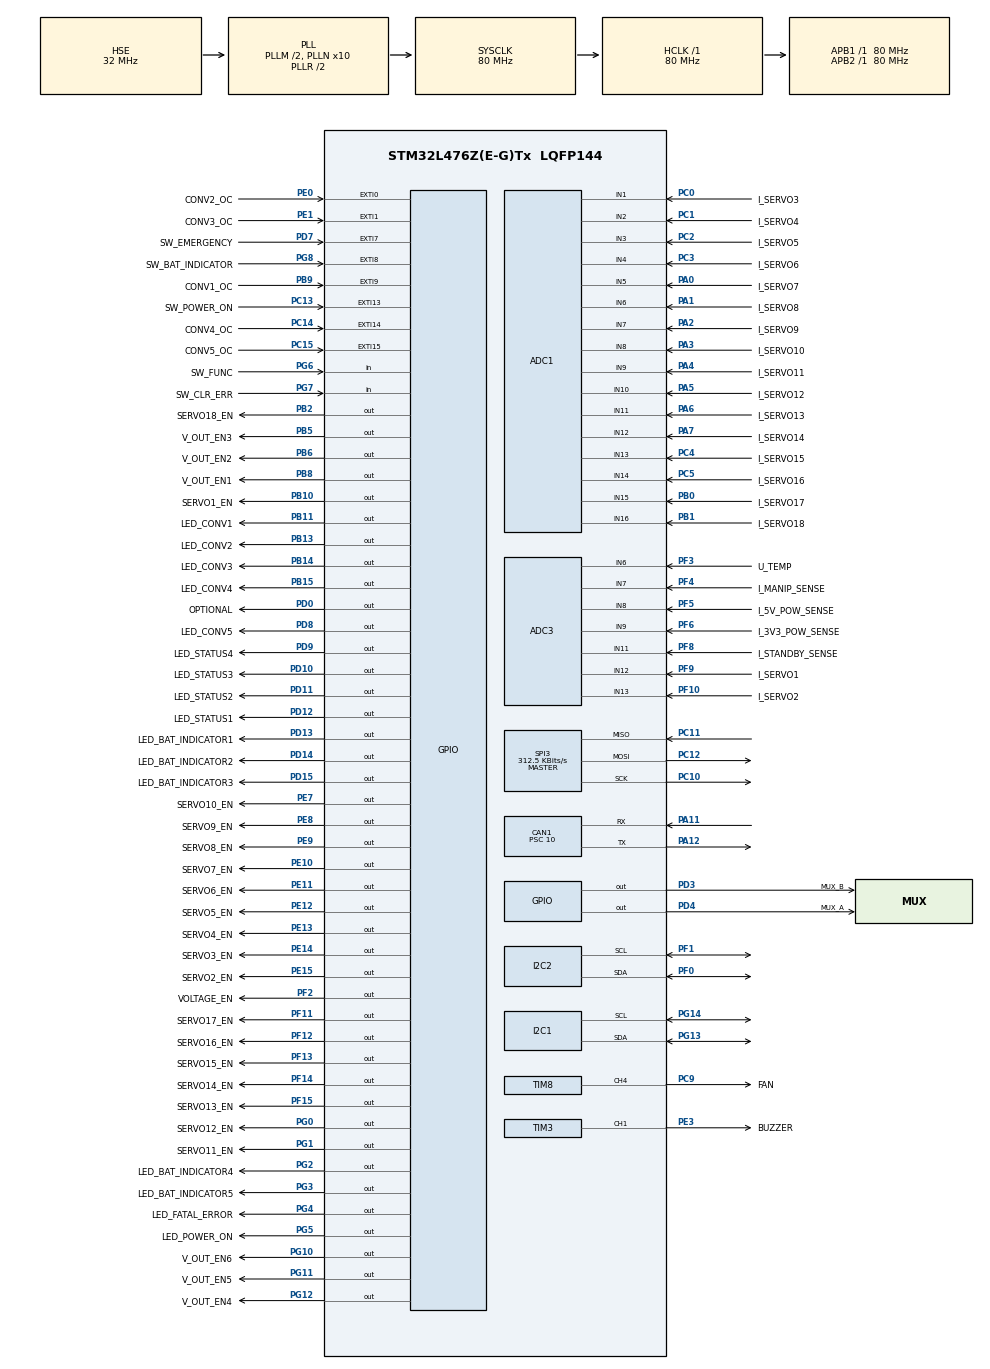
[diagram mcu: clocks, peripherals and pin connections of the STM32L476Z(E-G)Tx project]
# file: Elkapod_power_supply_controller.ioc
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ADC1.Channel-0\#ChannelRegularConversion=ADC_CHANNEL_1
ADC1.Channel-1\#ChannelRegularConversion=ADC_CHANNEL_2
ADC1.Channel-10\#ChannelRegularConversion=ADC_CHANNEL_11
ADC1.Channel-11\#ChannelRegularConversion=ADC_CHANNEL_12
ADC1.Channel-12\#ChannelRegularConversion=ADC_CHANNEL_13
ADC1.Channel-13\#ChannelRegularConversion=ADC_CHANNEL_14
ADC1.Channel-14\#ChannelRegularConversion=ADC_CHANNEL_15
ADC1.Channel-15\#ChannelRegularConversion=ADC_CHANNEL_16
ADC1.Channel-2\#ChannelRegularConversion=ADC_CHANNEL_3
ADC1.Channel-3\#ChannelRegularConversion=ADC_CHANNEL_4
ADC1.Channel-4\#ChannelRegularConversion=ADC_CHANNEL_5
ADC1.Channel-5\#ChannelRegularConversion=ADC_CHANNEL_6
ADC1.Channel-6\#ChannelRegularConversion=ADC_CHANNEL_7
ADC1.Channel-7\#ChannelRegularConversion=ADC_CHANNEL_8
ADC1.Channel-8\#ChannelRegularConversion=ADC_CHANNEL_9
ADC1.Channel-9\#ChannelRegularConversion=ADC_CHANNEL_10
ADC1.ClockPrescaler=ADC_CLOCK_ASYNC_DIV4
ADC1.ContinuousConvMode=DISABLE
ADC1.DMAContinuousRequests=DISABLE
ADC1.EOCSelection=ADC_EOC_SEQ_CONV
ADC1.ExternalTrigConv=ADC_SOFTWARE_START
ADC1.NbrOfConversion=16
ADC1.NbrOfConversionFlag=1
ADC1.OffsetNumber-0\#ChannelRegularConversion=ADC_OFFSET_NONE
ADC1.OffsetNumber-1\#ChannelRegularConversion=ADC_OFFSET_NONE
ADC1.OffsetNumber-10\#ChannelRegularConversion=ADC_OFFSET_NONE
ADC1.OffsetNumber-11\#ChannelRegularConversion=ADC_OFFSET_NONE
ADC1.OffsetNumber-12\#ChannelRegularConversion=ADC_OFFSET_NONE
ADC1.OffsetNumber-13\#ChannelRegularConversion=ADC_OFFSET_NONE
ADC1.OffsetNumber-14\#ChannelRegularConversion=ADC_OFFSET_NONE
ADC1.OffsetNumber-15\#ChannelRegularConversion=ADC_OFFSET_NONE
ADC1.OffsetNumber-2\#ChannelRegularConversion=ADC_OFFSET_NONE
ADC1.OffsetNumber-3\#ChannelRegularConversion=ADC_OFFSET_NONE
ADC1.OffsetNumber-4\#ChannelRegularConversion=ADC_OFFSET_NONE
ADC1.OffsetNumber-5\#ChannelRegularConversion=ADC_OFFSET_NONE
ADC1.OffsetNumber-6\#ChannelRegularConversion=ADC_OFFSET_NONE
ADC1.OffsetNumber-7\#ChannelRegularConversion=ADC_OFFSET_NONE
ADC1.OffsetNumber-8\#ChannelRegularConversion=ADC_OFFSET_NONE
ADC1.OffsetNumber-9\#ChannelRegularConversion=ADC_OFFSET_NONE
ADC1.Overrun=ADC_OVR_DATA_PRESERVED
ADC1.OversamplingMode=DISABLE
ADC1.Rank-0\#ChannelRegularConversion=1
ADC1.Rank-1\#ChannelRegularConversion=2
ADC1.Rank-10\#ChannelRegularConversion=11
ADC1.Rank-11\#ChannelRegularConversion=12
ADC1.Rank-12\#ChannelRegularConversion=13
ADC1.Rank-13\#ChannelRegularConversion=14
ADC1.Rank-14\#ChannelRegularConversion=15
ADC1.Rank-15\#ChannelRegularConversion=16
ADC1.Rank-2\#ChannelRegularConversion=3
ADC1.Rank-3\#ChannelRegularConversion=4
ADC1.Rank-4\#ChannelRegularConversion=5
ADC1.Rank-5\#ChannelRegularConversion=6
ADC1.Rank-6\#ChannelRegularConversion=7
ADC1.Rank-7\#ChannelRegularConversion=8
ADC1.Rank-8\#ChannelRegularConversion=9
ADC1.Rank-9\#ChannelRegularConversion=10
ADC1.SamplingTime-0\#ChannelRegularConversion=ADC_SAMPLETIME_12CYCLES_5
ADC1.SamplingTime-1\#ChannelRegularConversion=ADC_SAMPLETIME_12CYCLES_5
ADC1.SamplingTime-10\#ChannelRegularConversion=ADC_SAMPLETIME_12CYCLES_5
ADC1.SamplingTime-11\#ChannelRegularConversion=ADC_SAMPLETIME_12CYCLES_5
ADC1.SamplingTime-12\#ChannelRegularConversion=ADC_SAMPLETIME_12CYCLES_5
ADC1.SamplingTime-13\#ChannelRegularConversion=ADC_SAMPLETIME_12CYCLES_5
ADC1.SamplingTime-14\#ChannelRegularConversion=ADC_SAMPLETIME_12CYCLES_5
ADC1.SamplingTime-15\#ChannelRegularConversion=ADC_SAMPLETIME_12CYCLES_5
ADC1.SamplingTime-2\#ChannelRegularConversion=ADC_SAMPLETIME_12CYCLES_5
ADC1.SamplingTime-3\#ChannelRegularConversion=ADC_SAMPLETIME_12CYCLES_5
ADC1.SamplingTime-4\#ChannelRegularConversion=ADC_SAMPLETIME_12CYCLES_5
ADC1.SamplingTime-5\#ChannelRegularConversion=ADC_SAMPLETIME_12CYCLES_5
ADC1.SamplingTime-6\#ChannelRegularConversion=ADC_SAMPLETIME_12CYCLES_5
ADC1.SamplingTime-7\#ChannelRegularConversion=ADC_SAMPLETIME_12CYCLES_5
ADC1.SamplingTime-8\#ChannelRegularConversion=ADC_SAMPLETIME_12CYCLES_5
ADC1.SamplingTime-9\#ChannelRegularConversion=ADC_SAMPLETIME_12CYCLES_5
ADC1.master=1
ADC3.Channel-1\#ChannelRegularConversion=ADC_CHANNEL_6
ADC3.Channel-2\#ChannelRegularConversion=ADC_CHANNEL_7
ADC3.Channel-3\#ChannelRegularConversion=ADC_CHANNEL_8
ADC3.Channel-4\#ChannelRegularConversion=ADC_CHANNEL_9
ADC3.Channel-5\#ChannelRegularConversion=ADC_CHANNEL_11
ADC3.Channel-6\#ChannelRegularConversion=ADC_CHANNEL_12
ADC3.Channel-7\#ChannelRegularConversion=ADC_CHANNEL_13
ADC3.ClockPrescaler=ADC_CLOCK_ASYNC_DIV4
ADC3.EOCSelection=ADC_EOC_SEQ_CONV
ADC3.NbrOfConversion=7
ADC3.NbrOfConversionFlag=1
ADC3.OffsetNumber-1\#ChannelRegularConversion=ADC_OFFSET_NONE
ADC3.OffsetNumber-2\#ChannelRegularConversion=ADC_OFFSET_NONE
ADC3.OffsetNumber-3\#ChannelRegularConversion=ADC_OFFSET_NONE
ADC3.OffsetNumber-4\#ChannelRegularConversion=ADC_OFFSET_NONE
ADC3.OffsetNumber-5\#ChannelRegularConversion=ADC_OFFSET_NONE
ADC3.OffsetNumber-6\#ChannelRegularConversion=ADC_OFFSET_NONE
ADC3.OffsetNumber-7\#ChannelRegularConversion=ADC_OFFSET_NONE
ADC3.Rank-1\#ChannelRegularConversion=1
ADC3.Rank-2\#ChannelRegularConversion=2
ADC3.Rank-3\#ChannelRegularConversion=3
ADC3.Rank-4\#ChannelRegularConversion=4
ADC3.Rank-5\#ChannelRegularConversion=5
ADC3.Rank-6\#ChannelRegularConversion=6
ADC3.Rank-7\#ChannelRegularConversion=7
ADC3.SamplingTime-1\#ChannelRegularConversion=ADC_SAMPLETIME_12CYCLES_5
ADC3.SamplingTime-2\#ChannelRegularConversion=ADC_SAMPLETIME_12CYCLES_5
ADC3.SamplingTime-3\#ChannelRegularConversion=ADC_SAMPLETIME_12CYCLES_5
ADC3.SamplingTime-4\#ChannelRegularConversion=ADC_SAMPLETIME_12CYCLES_5
ADC3.SamplingTime-5\#ChannelRegularConversion=ADC_SAMPLETIME_12CYCLES_5
ADC3.SamplingTime-6\#ChannelRegularConversion=ADC_SAMPLETIME_12CYCLES_5
ADC3.SamplingTime-7\#ChannelRegularConversion=ADC_SAMPLETIME_12CYCLES_5
CAN1.AWUM=ENABLE
CAN1.BS1=CAN_BS1_6TQ
CAN1.CalculateBaudRate=1000000
CAN1.CalculateTimeBit=1000
CAN1.CalculateTimeQuantum=125.0
CAN1.NART=ENABLE
CAN1.Prescaler=10
Dma.ADC1.0.Direction=DMA_PERIPH_TO_MEMORY
Dma.ADC1.0.Instance=DMA1_Channel1
Dma.ADC1.0.MemDataAlignment=DMA_MDATAALIGN_HALFWORD
Dma.ADC1.0.MemInc=DMA_MINC_ENABLE
Dma.ADC1.0.Mode=DMA_NORMAL
Dma.ADC1.0.PeriphDataAlignment=DMA_PDATAALIGN_HALFWORD
Dma.ADC1.0.PeriphInc=DMA_PINC_DISABLE
Dma.ADC1.0.Priority=DMA_PRIORITY_MEDIUM
Dma.ADC3.5.Direction=DMA_PERIPH_TO_MEMORY
Dma.ADC3.5.Instance=DMA1_Channel3
Dma.ADC3.5.MemDataAlignment=DMA_MDATAALIGN_HALFWORD
Dma.ADC3.5.MemInc=DMA_MINC_ENABLE
Dma.ADC3.5.Mode=DMA_NORMAL
Dma.ADC3.5.PeriphDataAlignment=DMA_PDATAALIGN_HALFWORD
Dma.ADC3.5.PeriphInc=DMA_PINC_DISABLE
Dma.ADC3.5.Priority=DMA_PRIORITY_MEDIUM
Dma.I2C2_RX.1.Direction=DMA_PERIPH_TO_MEMORY
Dma.I2C2_RX.1.Instance=DMA1_Channel5
Dma.I2C2_RX.1.MemDataAlignment=DMA_MDATAALIGN_BYTE
Dma.I2C2_RX.1.MemInc=DMA_MINC_ENABLE
Dma.I2C2_RX.1.Mode=DMA_NORMAL
Dma.I2C2_RX.1.PeriphDataAlignment=DMA_PDATAALIGN_BYTE
Dma.I2C2_RX.1.PeriphInc=DMA_PINC_DISABLE
Dma.I2C2_RX.1.Priority=DMA_PRIORITY_HIGH
Dma.I2C2_TX.2.Direction=DMA_MEMORY_TO_PERIPH
Dma.I2C2_TX.2.Instance=DMA1_Channel4
Dma.I2C2_TX.2.MemDataAlignment=DMA_MDATAALIGN_BYTE
Dma.I2C2_TX.2.MemInc=DMA_MINC_DISABLE
Dma.I2C2_TX.2.Mode=DMA_NORMAL
Dma.I2C2_TX.2.PeriphDataAlignment=DMA_PDATAALIGN_BYTE
Dma.I2C2_TX.2.PeriphInc=DMA_PINC_DISABLE
Dma.I2C2_TX.2.Priority=DMA_PRIORITY_HIGH
Dma.Request0=ADC1
Dma.Request1=I2C2_RX
Dma.Request2=I2C2_TX
Dma.Request3=SPI3_RX
Dma.Request4=SPI3_TX
Dma.Request5=ADC3
Dma.SPI3_RX.3.Direction=DMA_PERIPH_TO_MEMORY
Dma.SPI3_RX.3.Instance=DMA2_Channel1
Dma.SPI3_RX.3.MemDataAlignment=DMA_MDATAALIGN_BYTE
Dma.SPI3_RX.3.MemInc=DMA_MINC_ENABLE
Dma.SPI3_RX.3.Mode=DMA_NORMAL
Dma.SPI3_RX.3.PeriphDataAlignment=DMA_PDATAALIGN_BYTE
Dma.SPI3_RX.3.PeriphInc=DMA_PINC_DISABLE
Dma.SPI3_RX.3.Priority=DMA_PRIORITY_HIGH
Dma.SPI3_TX.4.Direction=DMA_MEMORY_TO_PERIPH
Dma.SPI3_TX.4.Instance=DMA2_Channel2
Dma.SPI3_TX.4.MemDataAlignment=DMA_MDATAALIGN_BYTE
Dma.SPI3_TX.4.MemInc=DMA_MINC_ENABLE
Dma.SPI3_TX.4.Mode=DMA_NORMAL
Dma.SPI3_TX.4.PeriphDataAlignment=DMA_PDATAALIGN_BYTE
Dma.SPI3_TX.4.PeriphInc=DMA_PINC_DISABLE
Dma.SPI3_TX.4.Priority=DMA_PRIORITY_HIGH
I2C1.Timing=0x10D19CE4
I2C2.Analog_Filter=I2C_ANALOGFILTER_DISABLE
I2C2.Timing=0x10D19EE6
Mcu.Family=STM32L4
Mcu.Name=STM32L476Z(E-G)Tx
Mcu.Package=LQFP144
NVIC.CAN1_RX0_IRQn=true\:0\:0\:false\:false\:true\:true\:true\:true
NVIC.DMA1_Channel1_IRQn=true\:0\:0\:false\:false\:true\:false\:true\:true
NVIC.DMA1_Channel3_IRQn=true\:0\:0\:false\:false\:true\:false\:true\:true
NVIC.DMA1_Channel4_IRQn=true\:0\:0\:false\:false\:true\:false\:true\:true
NVIC.DMA1_Channel5_IRQn=true\:0\:0\:false\:false\:true\:false\:true\:true
NVIC.DMA2_Channel1_IRQn=true\:0\:0\:false\:false\:true\:false\:true\:true
NVIC.DMA2_Channel2_IRQn=true\:0\:0\:false\:false\:true\:false\:true\:true
NVIC.EXTI0_IRQn=true\:0\:0\:false\:false\:true\:true\:true\:true
NVIC.EXTI15_10_IRQn=true\:0\:0\:false\:false\:true\:true\:true\:true
NVIC.EXTI1_IRQn=true\:0\:0\:false\:false\:true\:true\:true\:true
NVIC.EXTI9_5_IRQn=true\:0\:0\:false\:false\:true\:true\:true\:true
NVIC.I2C2_ER_IRQn=true\:0\:0\:false\:false\:true\:true\:true\:true
NVIC.I2C2_EV_IRQn=true\:0\:0\:false\:false\:true\:true\:true\:true
NVIC.PriorityGroup=NVIC_PRIORITYGROUP_4
NVIC.TIM1_TRG_COM_TIM17_IRQn=true\:0\:0\:false\:false\:true\:true\:true\:true
NVIC.TIM7_IRQn=true\:0\:0\:false\:false\:true\:true\:true\:true
PA0.GPIO_Label=I_SERVO7
PA0.Signal=ADCx_IN5
PA1.GPIO_Label=I_SERVO8
PA1.Signal=ADCx_IN6
PA11.Mode=CAN_Activate
PA11.Signal=CAN1_RX
PA12.Mode=CAN_Activate
PA12.Signal=CAN1_TX
PA13\ (JTMS-SWDIO).Mode=Serial_Wire
PA13\ (JTMS-SWDIO).Signal=SYS_JTMS-SWDIO
PA14\ (JTCK-SWCLK).Mode=Serial_Wire
PA14\ (JTCK-SWCLK).Signal=SYS_JTCK-SWCLK
PA2.GPIO_Label=I_SERVO9
PA2.Signal=ADCx_IN7
PA3.GPIO_Label=I_SERVO10
PA3.Signal=ADCx_IN8
PA4.GPIO_Label=I_SERVO11
PA4.Signal=ADCx_IN9
PA5.GPIO_Label=I_SERVO12
PA5.Signal=ADCx_IN10
PA6.GPIO_Label=I_SERVO13
PA6.Signal=ADCx_IN11
PA7.GPIO_Label=I_SERVO14
PA7.Signal=ADCx_IN12
PB0.GPIO_Label=I_SERVO17
PB0.Signal=ADCx_IN15
PB1.GPIO_Label=I_SERVO18
PB1.Signal=ADCx_IN16
PB10.GPIO_Label=SERVO1_EN
PB10.Signal=GPIO_Output
PB11.GPIO_Label=LED_CONV1
PB11.Signal=GPIO_Output
PB13.GPIO_Label=LED_CONV2
PB13.Signal=GPIO_Output
PB14.GPIO_Label=LED_CONV3
PB14.Signal=GPIO_Output
PB15.GPIO_Label=LED_CONV4
PB15.Signal=GPIO_Output
PB2.GPIO_Label=SERVO18_EN
PB2.Signal=GPIO_Output
PB3\ (JTDO-TRACESWO).Signal=SYS_JTDO-SWO
PB5.GPIO_Label=V_OUT_EN3
PB5.Signal=GPIO_Output
PB6.GPIO_Label=V_OUT_EN2
PB6.Signal=GPIO_Output
PB8.GPIO_Label=V_OUT_EN1
PB8.Signal=GPIO_Output
PB9.GPIO_Label=CONV1_OC
PB9.Signal=GPXTI9
PC0.GPIO_Label=I_SERVO3
PC0.Signal=ADCx_IN1
PC1.GPIO_Label=I_SERVO4
PC1.Signal=ADCx_IN2
PC10.Mode=Full_Duplex_Master
PC10.Signal=SPI3_SCK
PC11.Mode=Full_Duplex_Master
PC11.Signal=SPI3_MISO
PC12.Mode=Full_Duplex_Master
PC12.Signal=SPI3_MOSI
PC13.GPIO_Label=SW_POWER_ON
PC13.GPIO_ModeDefaultEXTI=GPIO_MODE_IT_FALLING
PC13.Signal=GPXTI13
PC14-OSC32_IN\ (PC14).GPIO_Label=CONV4_OC
PC14-OSC32_IN\ (PC14).Signal=GPXTI14
PC15-OSC32_OUT\ (PC15).GPIO_Label=CONV5_OC
PC15-OSC32_OUT\ (PC15).Signal=GPXTI15
PC2.GPIO_Label=I_SERVO5
PC2.Signal=ADCx_IN3
PC3.GPIO_Label=I_SERVO6
PC3.Signal=ADCx_IN4
PC4.GPIO_Label=I_SERVO15
PC4.Signal=ADCx_IN13
PC5.GPIO_Label=I_SERVO16
PC5.Signal=ADCx_IN14
PC9.GPIO_Label=FAN
PC9.GPIO_Speed=GPIO_SPEED_FREQ_MEDIUM
PC9.Signal=S_TIM8_CH4
PD0.GPIO_Label=OPTIONAL
PD0.Signal=GPIO_Output
PD10.GPIO_Label=LED_STATUS3
PD10.Signal=GPIO_Output
PD11.GPIO_Label=LED_STATUS2
PD11.Signal=GPIO_Output
PD12.GPIO_Label=LED_STATUS1
PD12.Signal=GPIO_Output
PD13.GPIO_Label=LED_BAT_INDICATOR1
PD13.Signal=GPIO_Output
PD14.GPIO_Label=LED_BAT_INDICATOR2
PD14.Signal=GPIO_Output
PD15.GPIO_Label=LED_BAT_INDICATOR3
PD15.Signal=GPIO_Output
PD3.GPIO_Label=MUX_B
PD3.Signal=GPIO_Output
PD4.GPIO_Label=MUX_A
PD4.Signal=GPIO_Output
PD7.GPIO_Label=SW_EMERGENCY
PD7.GPIO_ModeDefaultEXTI=GPIO_MODE_IT_FALLING
PD7.Signal=GPXTI7
PD8.GPIO_Label=LED_CONV5
PD8.Signal=GPIO_Output
PD9.GPIO_Label=LED_STATUS4
PD9.Signal=GPIO_Output
PE0.GPIO_Label=CONV2_OC
PE0.Signal=GPXTI0
PE1.GPIO_Label=CONV3_OC
PE1.Signal=GPXTI1
PE10.GPIO_Label=SERVO7_EN
PE10.Signal=GPIO_Output
PE11.GPIO_Label=SERVO6_EN
PE11.Signal=GPIO_Output
PE12.GPIO_Label=SERVO5_EN
PE12.Signal=GPIO_Output
PE13.GPIO_Label=SERVO4_EN
PE13.Signal=GPIO_Output
PE14.GPIO_Label=SERVO3_EN
PE14.Signal=GPIO_Output
PE15.GPIO_Label=SERVO2_EN
PE15.Signal=GPIO_Output
PE3.GPIO_Label=BUZZER
PE3.GPIO_Speed=GPIO_SPEED_FREQ_MEDIUM
PE3.Signal=S_TIM3_CH1
PE7.GPIO_Label=SERVO10_EN
PE7.Signal=GPIO_Output
PE8.GPIO_Label=SERVO9_EN
PE8.Signal=GPIO_Output
PE9.GPIO_Label=SERVO8_EN
PE9.Signal=GPIO_Output
PF0.Mode=I2C
PF0.Signal=I2C2_SDA
PF1.Mode=I2C
PF1.Signal=I2C2_SCL
PF10.GPIO_Label=I_SERVO2
PF10.Mode=IN13-Single-Ended
PF10.Signal=ADC3_IN13
PF11.GPIO_Label=SERVO17_EN
PF11.Signal=GPIO_Output
PF12.GPIO_Label=SERVO16_EN
PF12.Signal=GPIO_Output
PF13.GPIO_Label=SERVO15_EN
PF13.Signal=GPIO_Output
PF14.GPIO_Label=SERVO14_EN
PF14.Signal=GPIO_Output
PF15.GPIO_Label=SERVO13_EN
PF15.Signal=GPIO_Output
PF2.GPIO_Label=VOLTAGE_EN
PF2.Signal=GPIO_Output
PF3.GPIO_Label=U_TEMP
PF3.Mode=IN6-Single-Ended
PF3.Signal=ADC3_IN6
PF4.GPIO_Label=I_MANIP_SENSE
PF4.Mode=IN7-Single-Ended
PF4.Signal=ADC3_IN7
PF5.GPIO_Label=I_5V_POW_SENSE
PF5.Mode=IN8-Single-Ended
PF5.Signal=ADC3_IN8
PF6.GPIO_Label=I_3V3_POW_SENSE
PF6.Mode=IN9-Single-Ended
PF6.Signal=ADC3_IN9
PF8.GPIO_Label=I_STANDBY_SENSE
PF8.Mode=IN11-Single-Ended
PF8.Signal=ADC3_IN11
PF9.GPIO_Label=I_SERVO1
PF9.Mode=IN12-Single-Ended
PF9.Signal=ADC3_IN12
PG0.GPIO_Label=SERVO12_EN
PG0.Signal=GPIO_Output
PG1.GPIO_Label=SERVO11_EN
PG1.Signal=GPIO_Output
PG10.GPIO_Label=V_OUT_EN6
PG10.Signal=GPIO_Output
PG11.GPIO_Label=V_OUT_EN5
PG11.Signal=GPIO_Output
PG12.GPIO_Label=V_OUT_EN4
PG12.Signal=GPIO_Output
PG13.Mode=I2C
PG13.Signal=I2C1_SDA
PG14.Mode=I2C
PG14.Signal=I2C1_SCL
PG2.GPIO_Label=LED_BAT_INDICATOR4
PG2.Signal=GPIO_Output
PG3.GPIO_Label=LED_BAT_INDICATOR5
PG3.Signal=GPIO_Output
PG4.GPIO_Label=LED_FATAL_ERROR
PG4.Signal=GPIO_Output
PG5.GPIO_Label=LED_POWER_ON
PG5.Signal=GPIO_Output
PG6.GPIO_Label=SW_FUNC
PG6.Signal=GPIO_Input
PG7.GPIO_Label=SW_CLR_ERR
PG7.Signal=GPIO_Input
PG8.GPIO_Label=SW_BAT_INDICATOR
PG8.GPIO_ModeDefaultEXTI=GPIO_MODE_IT_FALLING
PG8.Signal=GPXTI8
PH0-OSC_IN\ (PH0).Mode=HSE-External-Oscillator
PH0-OSC_IN\ (PH0).Signal=RCC_OSC_IN
PH1-OSC_OUT\ (PH1).Mode=HSE-External-Oscillator
PH1-OSC_OUT\ (PH1).Signal=RCC_OSC_OUT
ProjectManager.HeapSize=0x200
ProjectManager.StackSize=0x400
ProjectManager.TargetToolchain=STM32CubeIDE
RCC.ADCFreq_Value=64000000
RCC.AHBFreq_Value=80000000
RCC.APB1Freq_Value=80000000
RCC.APB1TimFreq_Value=80000000
RCC.APB2Freq_Value=80000000
RCC.APB2TimFreq_Value=80000000
RCC.CortexFreq_Value=80000000
RCC.HCLKFreq_Value=80000000
RCC.HSE_VALUE=32000000
RCC.HSI_VALUE=16000000
RCC.LSE_VALUE=32768
RCC.MSI_VALUE=4000000
RCC.PLLM=2
RCC.PLLN=10
RCC.PLLSourceVirtual=RCC_PLLSOURCE_HSE
RCC.SYSCLKFreq_VALUE=80000000
RCC.SYSCLKSource=RCC_SYSCLKSOURCE_PLLCLK
RCC.USBFreq_Value=64000000
RCC.VCOOutputFreq_Value=160000000
SH.ADCx_IN1.0=ADC1_IN1,IN1-Single-Ended
SH.ADCx_IN10.0=ADC1_IN10,IN10-Single-Ended
SH.ADCx_IN11.0=ADC1_IN11,IN11-Single-Ended
SH.ADCx_IN12.0=ADC1_IN12,IN12-Single-Ended
SH.ADCx_IN13.0=ADC1_IN13,IN13-Single-Ended
SH.ADCx_IN14.0=ADC1_IN14,IN14-Single-Ended
SH.ADCx_IN15.0=ADC1_IN15,IN15-Single-Ended
SH.ADCx_IN16.0=ADC1_IN16,IN16-Single-Ended
SH.ADCx_IN2.0=ADC1_IN2,IN2-Single-Ended
SH.ADCx_IN3.0=ADC1_IN3,IN3-Single-Ended
SH.ADCx_IN4.0=ADC1_IN4,IN4-Single-Ended
SH.ADCx_IN5.0=ADC1_IN5,IN5-Single-Ended
SH.ADCx_IN6.0=ADC1_IN6,IN6-Single-Ended
SH.ADCx_IN7.0=ADC1_IN7,IN7-Single-Ended
SH.ADCx_IN8.0=ADC1_IN8,IN8-Single-Ended
SH.ADCx_IN9.0=ADC1_IN9,IN9-Single-Ended
SH.S_TIM3_CH1.0=TIM3_CH1,PWM Generation1 CH1
SH.S_TIM8_CH4.0=TIM8_CH4,PWM Generation4 CH4
SPI3.BaudRatePrescaler=SPI_BAUDRATEPRESCALER_256
SPI3.CalculateBaudRate=312.5 KBits/s
SPI3.DataSize=SPI_DATASIZE_8BIT
SPI3.Direction=SPI_DIRECTION_2LINES
SPI3.Mode=SPI_MODE_MASTER
SPI3.VirtualType=VM_MASTER
TIM17.Period=19
TIM17.Prescaler=9999
TIM3.Channel-PWM\ Generation1\ CH1=TIM_CHANNEL_1
TIM3.Period=999
TIM3.Prescaler=79
TIM7.Period=99
TIM7.Prescaler=7999
TIM7.TIM_MasterOutputTrigger=TIM_TRGO_UPDATE
TIM8.Channel-PWM\ Generation4\ CH4=TIM_CHANNEL_4
TIM8.Period=999
TIM8.Prescaler=159
VP_SYS_V_PVD_IN.Mode=Mode_PVD_Int
VP_TIM17_VS_ClockSourceINT.Mode=Enable_Timer
VP_TIM7_VS_ClockSourceINT.Mode=Enable_Timer
board=custom

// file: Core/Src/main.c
/* USER CODE BEGIN Header */
/**
 ******************************************************************************
 * @file           : main.c
 * @brief          : Main program body
 ******************************************************************************
 * @attention
 *
 * Copyright (c) 2025 STMicroelectronics.
 * All rights reserved.
 *
 * This software is licensed under terms that can be found in the LICENSE file
 * in the root directory of this software component.
 * If no LICENSE file comes with this software, it is provided AS-IS.
 *
 ******************************************************************************
 */
/* USER CODE END Header */
#include "main.h"
#include "adc.h"
#include "can.h"
#include "dma.h"
#include "i2c.h"
#include "spi.h"
#include "tim.h"
#include "gpio.h"

/* USER CODE BEGIN Includes */
#include "hardware_config.h"
#include "pcf8574.h"
#include "mcp4552.h"
#include "adc121s021.h"
#include "i2c_manager.h"
#include "can_app.h"
#include "can_logic.h"
#include "pots_controller.h"
#include "servos_controller.h"
#include "voltage_outputs_controller.h"
#include "buzzer_controller.h"
#include "sequences_functions.h"
#include "error_manager.h"
#include "buttons_leds.h"

/* USER CODE END Includes */

/* USER CODE BEGIN PV */

// peripherals structures
I2C_Manager hi2c2_mgr;

PCF8574_HandleTypeDef expander1;
PCF8574_HandleTypeDef expander2;

ADC121S021_HandleTypeDef spi_adcs[SPI_ADC_COUNT];

MCP4552_HandleTypeDef pot1;
MCP4552_HandleTypeDef pot2;
MCP4552_HandleTypeDef pot3;
MCP4552_HandleTypeDef pot4;

PotChannel pots[4] = {
		{&pot1, 128, 128, 2},
		{&pot2, 128, 128, 2},
		{&pot3, 128, 128, 2},
		{&pot4, 128, 128, 2}
};

ServoControllerState servos = {
		.target_mask = 0,
		.current_mask = 0,
		.done = 2
};

VoltageOutputsController vouts = {
		.current_mask = 0,
		.target_mask = 0,
		.done = 2
};

BuzzerController buzzer = {0};
ErrorManager errm = {0};

// buffers and variables for SPI ADCs
uint16_t spi_adc_samples[SPI_ADC_COUNT][SPI_ADC_AVG_SAMPLES] = {0};
uint8_t spi_adc_sample_index[SPI_ADC_COUNT] = {0};
float spi_adc_avg_values[SPI_ADC_COUNT] = {0.0f};

volatile uint8_t spi_current_adc = 0;
volatile uint8_t spi_adc_conversion_in_progress = 0;

volatile uint8_t spi_adc_measurement_cycle_done = 0;

// buffers and variables for STM ADCs
uint16_t adc1_buf[ADC1_CHANNELS] = {0};
uint16_t adc3_buf[ADC3_CHANNELS] = {0};

uint16_t adc1_samples[ADC1_CHANNELS][ADC_AVG_SAMPLES] = {0};
uint16_t adc3_samples[ADC3_CHANNELS][ADC_AVG_SAMPLES] = {0};

uint8_t adc1_index = 0;
uint8_t adc3_index = 0;

uint8_t adc1_done_samples = 0;
uint8_t adc3_done_samples = 0;

uint8_t measured_temperature = 0;

// measured values
float U_converter1 = 0.0f;
float U_converter2 = 0.0f;
float U_converter3 = 0.0f;
float U_converter4 = 0.0f;
float U_converter5 = 0.0f;
float I_supply = 0.0f;
float U_supply = 0.0f;
float U_bat_ADC = 0.0f;

float servo_currents[18] = {0.0f};
float I_manip = 0.0f;
float I_5V_pow = 0.0f;
float I_3V3_pow = 0.0f;
float I_standby = 0.0f;

float temperatures[3] = {0.0f};

// flags etc
uint8_t conv1_oc_status = 0;
uint8_t conv2_oc_status = 0;
uint8_t conv3_oc_status = 0;
uint8_t conv4_oc_status = 0;
uint8_t conv5_oc_status = 0;

uint8_t manip_conv_en = 0;
uint8_t manip_conv_en_done = 2;

uint32_t last_tick_toggle_en_conv = 0;

volatile uint8_t system_in_sleep = 0;
volatile uint8_t wake_up_sequence_request = 0;
volatile uint8_t power_off_sequence_request = 0;
volatile uint32_t last_sw_emergency_tick = 0;
volatile uint32_t last_sw_power_on_tick = 0;
volatile uint32_t last_sw_bat_indicator_tick = 0;
volatile uint32_t last_sleep_transition_tick = 0;

uint8_t turn_off_supply_request = 0;
volatile uint8_t pressed_off_button = 0;

volatile uint8_t bat_measurement_request_in_sleep = 0;

uint8_t fatal_error = 0;

/* USER CODE END PV */

void SystemClock_Config(void);
void PeriphCommonClock_Config(void);

/* USER CODE BEGIN 0 */
void spi_adc_read_callback(void* user, HAL_StatusTypeDef status, uint16_t value);

static inline float adc_to_current(uint16_t adc_val, float scale) {
	return (float)adc_val * scale;
}

static inline float adc_to_voltage(uint16_t adc_val, float scale) {
	return (float)adc_val * scale;
}

static inline float adc_to_temperature(uint16_t adc_val, float a, float b) {
	return (((float)adc_val/4095.0f)*3.3f - b)/a;
}

void Wakeup_From_Stop1(void) {
	HAL_ResumeTick();
	SystemClock_Config();
	PeriphCommonClock_Config();
	HAL_Delay(2);

	MX_GPIO_Init();
	MX_DMA_Init();
	HAL_Delay(1);

	MX_TIM3_Init();
	MX_TIM7_Init();
	MX_TIM8_Init();
	MX_TIM17_Init();
	HAL_Delay(1);

	MX_SPI3_Init();
	MX_I2C1_Init();
	MX_I2C2_Init();
	HAL_Delay(1);

	MX_ADC1_Init();
	MX_ADC3_Init();
	HAL_Delay(1);

	MX_CAN1_Init();
	HAL_Delay(1);

	HAL_ADCEx_Calibration_Start(&hadc1, ADC_SINGLE_ENDED);
	HAL_ADCEx_Calibration_Start(&hadc3, ADC_SINGLE_ENDED);

	system_in_sleep = 0;
}

void EnterStop1(void) {
	system_in_sleep = 1;
	HAL_SuspendTick();
	HAL_PWR_EnterSTOPMode(PWR_LOWPOWERREGULATOR_ON, PWR_STOPENTRY_WFI);
}

void Mask_EXTI_except_POWER_ON_and_BAT_INDICATOR(void) {
	HAL_NVIC_DisableIRQ(EXTI0_IRQn);      // CONV2_OC
	HAL_NVIC_DisableIRQ(EXTI1_IRQn);      // CONV3_OC
//	HAL_NVIC_DisableIRQ(EXTI9_5_IRQn);    // SW_EMERGENCY + CONV1_OC + SW_BAT_INDICATOR
}

void Unmask_all_EXTI(void) {
	HAL_NVIC_EnableIRQ(EXTI0_IRQn);
	HAL_NVIC_EnableIRQ(EXTI1_IRQn);
	HAL_NVIC_EnableIRQ(EXTI9_5_IRQn);
	HAL_NVIC_EnableIRQ(EXTI15_10_IRQn);   // POWER_ON + CONV4_OC + CONV5_OC
}

uint16_t converter_voltage_to_pot_value(float voltage, float R_FB1,
		float R_FB2, float R_FB3,
		float R_pot, float R_pot_offset) {
	float Re = R_FB2/((voltage/1.215f) - 1);
	float Rp = (R_FB1*R_FB3 - Re*(R_FB1 + R_FB3))/(Re - R_FB1) - R_pot_offset;
	float pot_value = Rp*256.0/R_pot;

	if(pot_value <= 0.0f) {
		pot_value = 0.0f;
	} else if (pot_value >= 256.0f) {
		pot_value = 256.0f;
	}
	return (uint16_t)pot_value;
}

/* USER CODE END 0 */

int main(void)
{

  /* USER CODE BEGIN 1 */
	uint16_t turn_off_supply_tick = 0;

  /* USER CODE END 1 */

  /* MCU Configuration--------------------------------------------------------*/

  /* Reset of all peripherals, Initializes the Flash interface and the Systick. */
  HAL_Init();

  /* Configure the system clock */
  SystemClock_Config();

  /* Configure the peripherals common clocks */
  PeriphCommonClock_Config();

  /* Initialize all configured peripherals */
  MX_GPIO_Init();
  MX_DMA_Init();
  MX_ADC1_Init();
  MX_ADC3_Init();
  MX_CAN1_Init();
  MX_I2C1_Init();
  MX_I2C2_Init();
  MX_SPI3_Init();
  MX_TIM3_Init();
  MX_TIM8_Init();
  MX_TIM17_Init();
  MX_TIM7_Init();
  /* USER CODE BEGIN 2 */
	HAL_ADCEx_Calibration_Start(&hadc1, ADC_SINGLE_ENDED);
	HAL_ADCEx_Calibration_Start(&hadc3, ADC_SINGLE_ENDED);

	I2C_Manager_Init(&hi2c2_mgr, &hi2c2);

	ErrorManager_Init();

	power_on_seqence();

	// Go to standby mode
	Mask_EXTI_except_POWER_ON_and_BAT_INDICATOR();
	EnterStop1();

  /* USER CODE END 2 */

  /* Infinite loop */
  /* USER CODE BEGIN WHILE */

	while (1)
	{
		// power off sequence
		if(power_off_sequence_request == 1) {
			last_sleep_transition_tick = HAL_GetTick();
			Mask_EXTI_except_POWER_ON_and_BAT_INDICATOR();
			power_off_sequence(!bat_measurement_request_in_sleep);
			power_off_sequence_request = 0;
			bat_measurement_request_in_sleep = 0;
			EnterStop1();
		}

		// power on sequence
		if(wake_up_sequence_request == 1) {
			last_sleep_transition_tick = HAL_GetTick();
			Wakeup_From_Stop1();
			wake_up_sequence();
			Unmask_all_EXTI();
			wake_up_sequence_request = 0;
		}

		// bat measurement in sleep sequence
		if(bat_measurement_request_in_sleep == 1) {
			Wakeup_From_Stop1();
			bat_measurement_in_sleep_sequence();
			power_off_sequence_request = 1;
			continue;
		}

		// turn off request from CAN
		if(turn_off_supply_request == 1) {
			if(turn_off_supply_tick >= TURN_OFF_POWER_SUPPLY_TICK_DELAY) {
				power_off_sequence_request = 1;
				turn_off_supply_request = 0;
				turn_off_supply_tick = 0;
			}
			turn_off_supply_tick++;
		}

		// set manipulator converter state
		if(manip_conv_en_done == 0) {
			if(manip_conv_en == 1) {
				PCF7485_write_pin_blocking(&expander1, EXPANDER1_CONV4_EN, GPIO_PIN_RESET);
				ErrorManager_RegistryConverterToggleState(CONV4);
			} else {
				PCF7485_write_pin_blocking(&expander1, EXPANDER1_CONV4_EN, GPIO_PIN_SET);
				ErrorManager_RegistryConverterToggleState(CONV4);
			}
			manip_conv_en_done = 1;
		}

		Pots_Tick(); // setting voltages in converters
		Servos_Tick();
		VoltageOutputs_Tick();
		Buzzer_Tick();
		ErrorManager_Tick();
		ButtonsLEDs_Tick();
		CAN_Logic_Tick();

		HAL_Delay(1);

    /* USER CODE END WHILE */

	}
}

void SystemClock_Config(void)
{
  RCC_OscInitTypeDef RCC_OscInitStruct = {0};
  RCC_ClkInitTypeDef RCC_ClkInitStruct = {0};

  /** Configure the main internal regulator output voltage
  */
  if (HAL_PWREx_ControlVoltageScaling(PWR_REGULATOR_VOLTAGE_SCALE1) != HAL_OK)
  {
    Error_Handler();
  }

  /** Initializes the RCC Oscillators according to the specified parameters
  * in the RCC_OscInitTypeDef structure.
  */
  RCC_OscInitStruct.OscillatorType = RCC_OSCILLATORTYPE_HSE;
  RCC_OscInitStruct.HSEState = RCC_HSE_ON;
  RCC_OscInitStruct.PLL.PLLState = RCC_PLL_ON;
  RCC_OscInitStruct.PLL.PLLSource = RCC_PLLSOURCE_HSE;
  RCC_OscInitStruct.PLL.PLLM = 2;
  RCC_OscInitStruct.PLL.PLLN = 10;
  RCC_OscInitStruct.PLL.PLLP = RCC_PLLP_DIV7;
  RCC_OscInitStruct.PLL.PLLQ = RCC_PLLQ_DIV2;
  RCC_OscInitStruct.PLL.PLLR = RCC_PLLR_DIV2;
  if (HAL_RCC_OscConfig(&RCC_OscInitStruct) != HAL_OK)
  {
    Error_Handler();
  }

  /** Initializes the CPU, AHB and APB buses clocks
  */
  RCC_ClkInitStruct.ClockType = RCC_CLOCKTYPE_HCLK|RCC_CLOCKTYPE_SYSCLK
                              |RCC_CLOCKTYPE_PCLK1|RCC_CLOCKTYPE_PCLK2;
  RCC_ClkInitStruct.SYSCLKSource = RCC_SYSCLKSOURCE_PLLCLK;
  RCC_ClkInitStruct.AHBCLKDivider = RCC_SYSCLK_DIV1;
  RCC_ClkInitStruct.APB1CLKDivider = RCC_HCLK_DIV1;
  RCC_ClkInitStruct.APB2CLKDivider = RCC_HCLK_DIV1;

  if (HAL_RCC_ClockConfig(&RCC_ClkInitStruct, FLASH_LATENCY_4) != HAL_OK)
  {
    Error_Handler();
  }
}

void PeriphCommonClock_Config(void)
{
  RCC_PeriphCLKInitTypeDef PeriphClkInit = {0};

  /** Initializes the peripherals clock
  */
  PeriphClkInit.PeriphClockSelection = RCC_PERIPHCLK_ADC;
  PeriphClkInit.AdcClockSelection = RCC_ADCCLKSOURCE_PLLSAI1;
  PeriphClkInit.PLLSAI1.PLLSAI1Source = RCC_PLLSOURCE_HSE;
  PeriphClkInit.PLLSAI1.PLLSAI1M = 2;
  PeriphClkInit.PLLSAI1.PLLSAI1N = 8;
  PeriphClkInit.PLLSAI1.PLLSAI1P = RCC_PLLP_DIV7;
  PeriphClkInit.PLLSAI1.PLLSAI1Q = RCC_PLLQ_DIV2;
  PeriphClkInit.PLLSAI1.PLLSAI1R = RCC_PLLR_DIV2;
  PeriphClkInit.PLLSAI1.PLLSAI1ClockOut = RCC_PLLSAI1_ADC1CLK;
  if (HAL_RCCEx_PeriphCLKConfig(&PeriphClkInit) != HAL_OK)
  {
    Error_Handler();
  }
}

/* USER CODE BEGIN 4 */

void HAL_GPIO_EXTI_Callback(uint16_t GPIO_Pin) {
	uint32_t now_tick = HAL_GetTick();

	if(GPIO_Pin == SW_POWER_ON_Pin && now_tick - last_sw_power_on_tick > EXTI_SW_TICK_DELAY) {
		if (system_in_sleep == 1) {
			wake_up_sequence_request = 1;
		} else {
			pressed_off_button = 1;
			Buzzer_Start(1, BUZZ_HIGH_SHORT);
		}
		last_sw_power_on_tick = now_tick;
		return;
	}

	if(GPIO_Pin == SW_EMERGENCY_Pin && now_tick - last_sw_emergency_tick > EXTI_SW_TICK_DELAY) {
		power_off_sequence_request = 1;
		last_sw_emergency_tick = now_tick;
		return;
	}

	if(GPIO_Pin == SW_BAT_INDICATOR_Pin && now_tick - last_sw_bat_indicator_tick > EXTI_SW_TICK_DELAY) {
		if (system_in_sleep == 1) {
			bat_measurement_request_in_sleep = 1;
			last_sw_bat_indicator_tick = now_tick;
		}
		return;
	}

	if(now_tick - last_sleep_transition_tick < SLEEP_TRANSITION_TICK_DELAY) {
		return;
	}

	ErrorManager_ConvOC_Notify(GPIO_Pin);
}

void HAL_TIM_PeriodElapsedCallback(TIM_HandleTypeDef *htim) {
	// timer for SPI ADCs conversions
	if(htim->Instance == TIM17) {
		if(!spi_adc_conversion_in_progress) {
			if(ADC121S021_read_start(&spi_adcs[spi_current_adc], spi_adc_read_callback,
					(void*)(uintptr_t)spi_current_adc) == HAL_OK) {
				spi_adc_conversion_in_progress = 1;
				spi_current_adc++;
				if(spi_current_adc >= SPI_ADC_COUNT) {
					spi_current_adc = 0;
				}

				return;
			}
		}
	}

	// timer for STM ADCs conversions
	if(htim->Instance == TIM7) {
		switch(measured_temperature) {
		case 0:
			HAL_GPIO_WritePin(MUX_A_GPIO_Port, MUX_A_Pin, GPIO_PIN_RESET);
			HAL_GPIO_WritePin(MUX_B_GPIO_Port, MUX_B_Pin, GPIO_PIN_RESET);
			break;
		case 1:
			HAL_GPIO_WritePin(MUX_A_GPIO_Port, MUX_A_Pin, GPIO_PIN_SET);
			HAL_GPIO_WritePin(MUX_B_GPIO_Port, MUX_B_Pin, GPIO_PIN_RESET);
			break;
		case 2:
			HAL_GPIO_WritePin(MUX_A_GPIO_Port, MUX_A_Pin, GPIO_PIN_RESET);
			HAL_GPIO_WritePin(MUX_B_GPIO_Port, MUX_B_Pin, GPIO_PIN_SET);
			break;
		}
		HAL_ADC_Start_DMA(&hadc1, (uint32_t*)adc1_buf, ADC1_CHANNELS);
	}

}

void HAL_ADC_ConvCpltCallback(ADC_HandleTypeDef *hadc) {
	if(hadc->Instance == ADC1) {
		for(uint8_t ch = 0; ch < ADC1_CHANNELS; ch++)
			adc1_samples[ch][adc1_index] = adc1_buf[ch];

		adc1_index = (adc1_index + 1) % ADC_AVG_SAMPLES;
		adc1_done_samples++;

		if(adc1_done_samples == ADC_AVG_SAMPLES) {
			float avg[ADC1_CHANNELS] = {0};
			for (uint8_t ch = 0; ch < ADC1_CHANNELS; ch++) {
				uint32_t sum = 0;
				for (uint8_t i = 0; i < ADC_AVG_SAMPLES; i++) {
					sum += adc1_samples[ch][i];
				}
				avg[ch] = (float)sum / ADC_AVG_SAMPLES;
			}

			servo_currents[2]  = adc_to_current(avg[I_SERVO3_ADC1_rank],  I_SERVO_COEFF);
			servo_currents[3]  = adc_to_current(avg[I_SERVO4_ADC1_rank],  I_SERVO_COEFF);
			servo_currents[4]  = adc_to_current(avg[I_SERVO5_ADC1_rank],  I_SERVO_COEFF);
			servo_currents[5]  = adc_to_current(avg[I_SERVO6_ADC1_rank],  I_SERVO_COEFF);
			servo_currents[6]  = adc_to_current(avg[I_SERVO7_ADC1_rank],  I_SERVO_COEFF);
			servo_currents[7]  = adc_to_current(avg[I_SERVO8_ADC1_rank],  I_SERVO_COEFF);
			servo_currents[8]  = adc_to_current(avg[I_SERVO9_ADC1_rank],  I_SERVO_COEFF);
			servo_currents[9]  = adc_to_current(avg[I_SERVO10_ADC1_rank], I_SERVO_COEFF);
			servo_currents[10] = adc_to_current(avg[I_SERVO11_ADC1_rank], I_SERVO_COEFF);
			servo_currents[11] = adc_to_current(avg[I_SERVO12_ADC1_rank], I_SERVO_COEFF);
			servo_currents[12] = adc_to_current(avg[I_SERVO13_ADC1_rank], I_SERVO_COEFF);
			servo_currents[13] = adc_to_current(avg[I_SERVO14_ADC1_rank], I_SERVO_COEFF);
			servo_currents[14] = adc_to_current(avg[I_SERVO15_ADC1_rank], I_SERVO_COEFF);
			servo_currents[15] = adc_to_current(avg[I_SERVO16_ADC1_rank], I_SERVO_COEFF);
			servo_currents[16] = adc_to_current(avg[I_SERVO17_ADC1_rank], I_SERVO_COEFF);
			servo_currents[17] = adc_to_current(avg[I_SERVO18_ADC1_rank], I_SERVO_COEFF);

			adc1_done_samples = 0;
		}

		HAL_ADC_Start_DMA(&hadc3, (uint32_t*)adc3_buf, ADC3_CHANNELS);

	} else if (hadc->Instance == ADC3) {
		for (uint8_t ch = 0; ch < ADC3_CHANNELS; ch++) {
			adc3_samples[ch][adc3_index] = adc3_buf[ch];
		}

		adc3_index = (adc3_index + 1) % ADC_AVG_SAMPLES;
		adc3_done_samples++;

		if(adc3_done_samples == ADC_AVG_SAMPLES) {
			float avg[ADC3_CHANNELS] = {0};
			for (uint8_t ch = 0; ch < ADC3_CHANNELS; ch++) {
				uint32_t sum = 0;
				for (uint8_t i = 0; i < ADC_AVG_SAMPLES; i++) {
					sum += adc3_samples[ch][i];
				}
				avg[ch] = (float)sum / ADC_AVG_SAMPLES;
			}

			I_manip  	  	  = adc_to_current(avg[I_MANIP_SENSE_ADC3_rank], I_MANIP_COEFF);
			I_5V_pow    	  = adc_to_current(avg[I_5V_POW_SENSE_ADC3_rank], I_5V_POW_COEFF);
			I_3V3_pow    	  = adc_to_current(avg[I_3V3_POW_SENSE_ADC3_rank], I_3V3_POW_COEFF);
			I_standby		  = adc_to_current(avg[I_STANDBY_SENSE_ADC3_rank], I_STANDBY_COEFF);
			servo_currents[0] = adc_to_current(avg[I_SERVO1_ADC3_rank], I_SERVO_COEFF);
			servo_currents[1] = adc_to_current(avg[I_SERVO2_ADC3_rank], I_SERVO_COEFF);

			temperatures[measured_temperature] = adc_to_temperature(avg[U_TEMP_ADC3_rank],
					TEMP_SENSOR_COEFF_A,
					TEMP_SENSOR_COEFF_B);
			adc3_done_samples = 0;

			measured_temperature++;
			if(measured_temperature >= TEMP_SENSOR_COUNT) {
				ErrorManager_CheckConverterTemps(temperatures);
				measured_temperature = 0;
			}

			ErrorManager_CheckServoCurrents(servo_currents);
		}
	}
}

void spi_adc_read_callback(void* user, HAL_StatusTypeDef status, uint16_t value) {
	uint8_t adc_index = (uint8_t)(uintptr_t)user;

	if(status == HAL_OK) {
		spi_adc_samples[adc_index][spi_adc_sample_index[adc_index]] = value;

		spi_adc_sample_index[adc_index]++;
		if(spi_adc_sample_index[adc_index] >= SPI_ADC_AVG_SAMPLES) {
			spi_adc_sample_index[adc_index] = 0;

			uint32_t sum = 0;
			for(uint8_t i = 0; i < SPI_ADC_AVG_SAMPLES; i++)
				sum += spi_adc_samples[adc_index][i];
			spi_adc_avg_values[adc_index] = (float)sum / SPI_ADC_AVG_SAMPLES;

			if(adc_index >= SPI_ADC_COUNT - 1) {
				U_converter1 = adc_to_voltage(spi_adc_avg_values[ADC1_CS_PIN], U_CONVERTER1_COEFF);
				U_converter2 = adc_to_voltage(spi_adc_avg_values[ADC2_CS_PIN], U_CONVERTER2_COEFF);
				U_converter3 = adc_to_voltage(spi_adc_avg_values[ADC3_CS_PIN], U_CONVERTER3_COEFF);
				U_converter4 = adc_to_voltage(spi_adc_avg_values[ADC4_CS_PIN], U_CONVERTER4_COEFF);
				U_converter5 = adc_to_voltage(spi_adc_avg_values[ADC5_CS_PIN], U_CONVERTER5_COEFF);
				I_supply 	 = adc_to_voltage(spi_adc_avg_values[ADC_I_SUPPLY_CS_PIN], I_SUPPLY_COEFF);
				U_supply	 = adc_to_voltage(spi_adc_avg_values[ADC_U_SUPPLY_CS_PIN], U_SUPPLY_COEFF);
				U_bat_ADC	 = adc_to_voltage(spi_adc_avg_values[ADC_U_BAT_CS_PIN], U_BAT_ADC_COEFF);

				ErrorManager_CheckSupplyVoltage(U_supply);
				spi_adc_measurement_cycle_done = 1;
			}
		}
	}
	spi_adc_conversion_in_progress = 0;
}

/* USER CODE END 4 */

void Error_Handler(void)
{
	__disable_irq();
	while (1)
	{
	}
}
